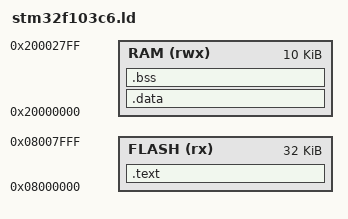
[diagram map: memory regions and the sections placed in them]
MEMORY
{
  FLASH (rx) : ORIGIN = 0x08000000, LENGTH = 32K
  RAM (rwx)  : ORIGIN = 0x20000000, LENGTH = 10K
}

ENTRY(reset_handler)

SECTIONS
{
  .text :
  {
    KEEP(*(.isr_vector))
    *(.text*)
    *(.rodata*)
    _etext = .;
  } > FLASH

  .data : AT(_etext)
  {
    _sdata = .;
    *(.data*)
    _edata = .;
  } > RAM

  .bss :
  {
    _sbss = .;
    *(.bss*)
    *(COMMON)
    _ebss = .;
  } > RAM
}
